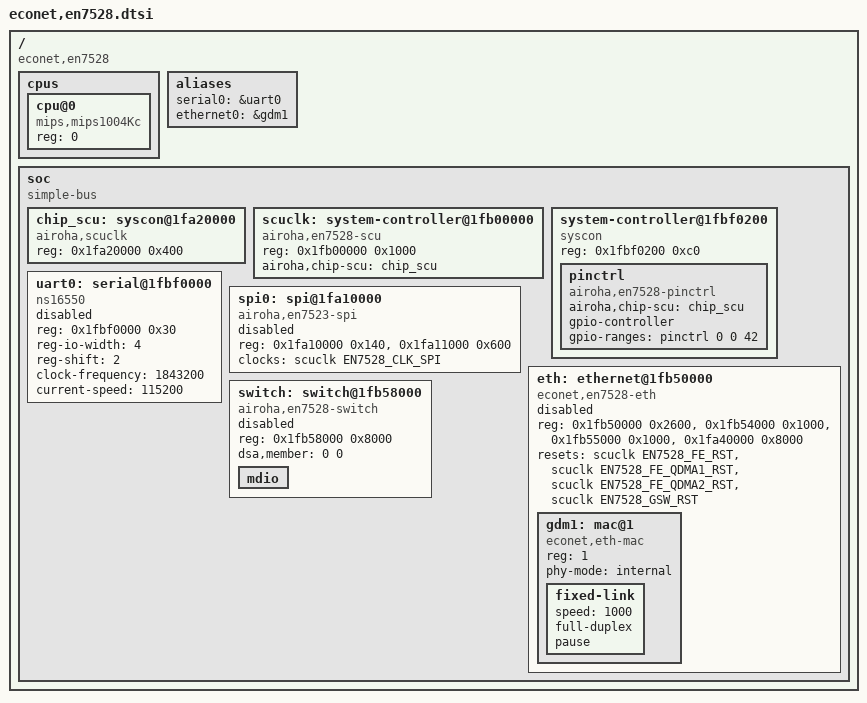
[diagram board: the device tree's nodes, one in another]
// SPDX-License-Identifier: (GPL-2.0-only OR BSD-2-Clause)

#include <dt-bindings/input/linux-event-codes.h>
#include <dt-bindings/interrupt-controller/irq.h>
#include <dt-bindings/gpio/gpio.h>
#include <dt-bindings/leds/common.h>
#include <dt-bindings/clock/econet,en7528-scu.h>
#include <dt-bindings/reset/econet,en7528-scu.h>

/ {
	compatible = "econet,en7528", "airoha,en7528";
	#address-cells = <1>;
	#size-cells = <1>;

	cpus {
		#address-cells = <1>;
		#size-cells = <0>;

		cpu@0 {
			compatible = "mips,mips1004Kc";
			device_type = "cpu";
			reg = <0>;
		};
	};

	aliases {
		serial0 = &uart0;
		ethernet0 = &gdm1;
	};

	soc {
		compatible = "simple-bus";
		#address-cells = <1>;
		#size-cells = <1>;
		ranges;

		chip_scu: syscon@1fa20000 {
			compatible = "airoha,scuclk", "airoha,en7528-chip-scu", "syscon";
			reg = <0x1fa20000 0x400>;
		};

		scuclk: system-controller@1fb00000 {
			compatible = "airoha,en7528-scu", "syscon";
			reg = <0x1fb00000 0x1000>;

			airoha,chip-scu = <&chip_scu>;
			#clock-cells = <1>;
			#reset-cells = <1>;
		};

		system-controller@1fbf0200 {
			compatible = "syscon", "simple-mfd";
			reg = <0x1fbf0200 0xc0>;

			pinctrl: pinctrl {
				compatible = "airoha,en7528-pinctrl";
				airoha,chip-scu = <&chip_scu>;

				gpio-controller;
				#gpio-cells = <2>;
				gpio-ranges = <&pinctrl 0 0 42>;
			};
		};

		uart0: serial@1fbf0000 {
			compatible = "ns16550";
			reg = <0x1fbf0000 0x30>;

			reg-io-width = <4>;
			reg-shift = <2>;

			clock-frequency = <1843200>;
			current-speed = <115200>;

			status = "disabled";
		};

		spi0: spi@1fa10000 {
			compatible = "airoha,en7523-spi";
			reg = <0x1fa10000 0x140>,
			      <0x1fa11000 0x600>;

			clocks = <&scuclk EN7528_CLK_SPI>;
			clock-names = "spi";

			#address-cells = <1>;
			#size-cells = <0>;

			status = "disabled";
		};

		eth: ethernet@1fb50000 {
			compatible = "econet,en7528-eth";
			status = "disabled";
			reg = <0x1fb50000 0x2600>,
			      <0x1fb54000 0x1000>,
			      <0x1fb55000 0x1000>,
			      <0x1fa40000 0x8000>;
			reg-names = "fe", "qdma0", "qdma1", "gdmp";

			resets = <&scuclk EN7528_FE_RST>,
				 <&scuclk EN7528_FE_QDMA1_RST>,
				 <&scuclk EN7528_FE_QDMA2_RST>,
				 <&scuclk EN7528_GSW_RST>;
			reset-names = "fe", "pdma", "qdma", "switch";

			#address-cells = <1>;
			#size-cells = <0>;

			gdm1: mac@1 {
				compatible = "econet,eth-mac";
				reg = <1>;
				phy-mode = "internal";

				fixed-link {
					speed = <1000>;
					full-duplex;
					pause;
				};
			};
		};

		switch: switch@1fb58000 {
			compatible = "airoha,en7528-switch";
			reg = <0x1fb58000 0x8000>;

			status = "disabled";

			#address-cells = <1>;
			#size-cells = <0>;
			dsa,member = <0 0>;

			mdio {
				#address-cells = <1>;
				#size-cells = <0>;
			};
		};
	};
};
